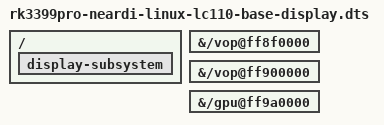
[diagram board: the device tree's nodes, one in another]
/dts-v1/;

/include/ "rk3399pro-neardi-linux-lc110-base.dts"

/ {
	display-subsystem {
		status = "okay";
	};
};

&{/vop@ff8f0000} {
	status = "okay";
};

&{/vop@ff900000} {
	status = "okay";
};

&{/gpu@ff9a0000} {
	status = "okay";
};
